# ATxmega384C3 device description
Architecture: AVR8_XMEGA; Family: AVR XMEGA
Registers are 8-bit, access not given, no defined reset value unless marked. A register's access mark holds for its fields unless they carry their own. Offsets are from the block's base; [hi:lo] are bit positions; {n}, {i} and the like mark numbered series; 'fields as' and 'values as' point back to an identical list.

## AWEX — Advanced Waveform Extension
Instances: AWEXC 0x880
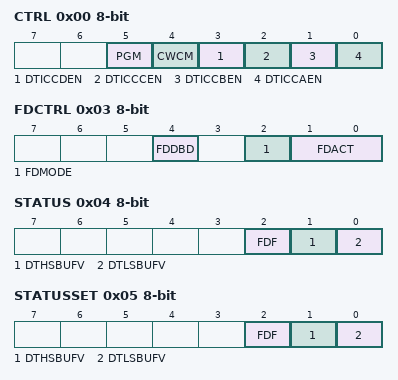
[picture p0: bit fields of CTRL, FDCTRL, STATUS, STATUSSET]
0x00 CTRL — Control Register
  [5] PGM — Pattern Generation Mode
  [4] CWCM — Common Waveform Channel Mode
  [3] DTICCDEN — Dead Time Insertion Compare Channel D Enable
  [2] DTICCCEN — Dead Time Insertion Compare Channel C Enable
  [1] DTICCBEN — Dead Time Insertion Compare Channel B Enable
  [0] DTICCAEN — Dead Time Insertion Compare Channel A Enable
0x02 FDEMASK — Fault Detection Event Mask
0x03 FDCTRL — Fault Detection Control Register
  [4] FDDBD — Fault Detect on Disable Break Disable
  [2] FDMODE — Fault Detect Mode
  [1:0] FDACT — Fault Detect Action
    0=NONE (No Fault Protection); 1=CLEAROE (Clear Output Enable Bits); 3=CLEARDIR (Clear I/O Port Direction Bits)
0x04 STATUS
  [2] FDF — Fault Detect Flag
  [1] DTHSBUFV — Dead Time High Side Buffer Valid
  [0] DTLSBUFV — Dead Time Low Side Buffer Valid
0x05 STATUSSET
  fields as STATUS
0x06 DTBOTH — Dead Time Both Sides
0x07 DTBOTHBUF — Dead Time Both Sides Buffer
0x08 DTLS — Dead Time Low Side
0x09 DTHS — Dead Time High Side
0x0A DTLSBUF — Dead Time Low Side Buffer
0x0B DTHSBUF — Dead Time High Side Buffer
0x0C OUTOVEN — Output Override Enable

## HIRES — High-Resolution Extension
Instances: HIRESC 0x890
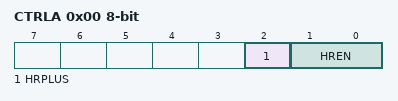
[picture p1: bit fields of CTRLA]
0x00 CTRLA — Control Register
  [2] HRPLUS — High Resolution Plus
  [1:0] HREN — High Resolution Enable
    0=NONE (No Fault Protection); 1=TC0 (Enable High Resolution on Timer/Counter 0); 2=TC1 (Enable High Resolution on Timer/Counter 1); 3=BOTH (Enable High Resolution both Timer/Counters)

## USART — Universal Synchronous/Asynchronous Receiver/Transmitter
Instances: USARTC0 0x8A0, USARTD0 0x9A0, USARTE0 0xAA0
0x00 DATA
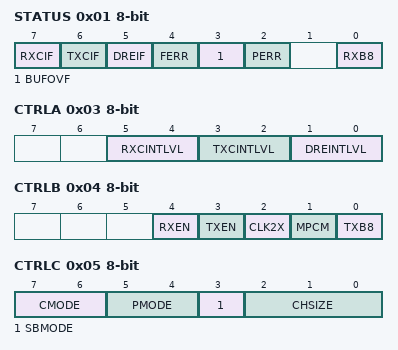
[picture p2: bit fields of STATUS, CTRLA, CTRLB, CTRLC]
0x01 STATUS
  [7] RXCIF — Receive Interrupt Flag
  [6] TXCIF — Transmit Interrupt Flag
  [5] DREIF — Data Register Empty Flag
  [4] FERR — Frame Error
  [3] BUFOVF — Buffer Overflow
  [2] PERR — Parity Error
  [0] RXB8 — Receive Bit 8
0x03 CTRLA — Control Register A
  [all] fields
    0=OFF (Interrupt Disabled); 1=LO (Low Level); 2=MED (Medium Level); 3=HI (High Level)
  [5:4] RXCINTLVL — Receive Interrupt Level
  [3:2] TXCINTLVL — Transmit Interrupt Level
  [1:0] DREINTLVL — Data Register Empty Interrupt Level
0x04 CTRLB — Control Register B
  [4] RXEN — Receiver Enable
  [3] TXEN — Transmitter Enable
  [2] CLK2X — Double transmission speed
  [1] MPCM — Multi-processor Communication Mode
  [0] TXB8 — Transmit bit 8
0x05 CTRLC — Control Register C
  [7:6] CMODE — Communication Mode
    0=ASYNCHRONOUS (Asynchronous Mode); 1=SYNCHRONOUS (Synchronous Mode); 2=IRDA (IrDA Mode); 3=MSPI (Master SPI Mode)
  [5:4] PMODE — Parity Mode
    0=DISABLED (No Parity); 2=EVEN (Even Parity); 3=ODD (Odd Parity)
  [3] SBMODE — Stop Bit Mode
  [2:0] CHSIZE — Character Size
    {v}={v+5}BIT (Character size: {v+5} bit) (v=0..3); 7=9BIT (Character size: 9 bit)
0x06 BAUDCTRLA — Baud Rate Control Register A
  [7:0] BSEL — Baud Rate Selection Bits [7:0]
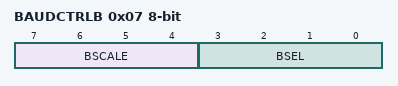
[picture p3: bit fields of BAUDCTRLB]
0x07 BAUDCTRLB — Baud Rate Control Register B
  [7:4] BSCALE — Baud Rate Scale
  [3:0] BSEL — Baud Rate Selection bits[11:8]

## SPI — Serial Peripheral Interface
Instances: SPIC 0x8C0, SPID 0x9C0
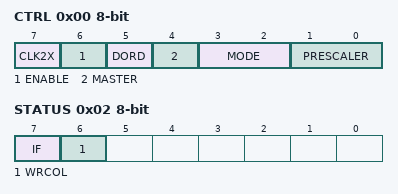
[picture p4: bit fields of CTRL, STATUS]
0x00 CTRL — Control Register
  [7] CLK2X — Enable Double Speed
  [6] ENABLE — Enable Module
  [5] DORD — Data Order Setting
  [4] MASTER — Master Operation Enable
  [3:2] MODE — SPI Mode
    {v}=SPI Mode {v} (v=0..3)
  [1:0] PRESCALER
    0=DIV4 (System Clock / 4); 1=DIV16 (System Clock / 16); 2=DIV64 (System Clock / 64); 3=DIV128 (System Clock / 128)
0x01 INTCTRL — Interrupt Control Register
  [1:0] INTLVL — Interrupt level
    0=OFF (Interrupt Disabled); 1=LO (Low Level); 2=MED (Medium Level); 3=HI (High Level)
0x02 STATUS
  [7] IF — Interrupt Flag
  [6] WRCOL — Write Collision
0x03 DATA

## IRCOM — IR Communication Module
Instances: IRCOM 0x8F8
0x00 CTRL — Control Register
  [3:0] EVSEL — Event Channel Select
    0=OFF (No Event Source); {v}=Event Channel {v-8} (v=8..11)
0x01 TXPLCTRL — IrDA Transmitter Pulse Length Control Register
0x02 RXPLCTRL — IrDA Receiver Pulse Length Control Register

## NVM_FUSES — Fuses
Instances: FUSE 0x00 in fuses
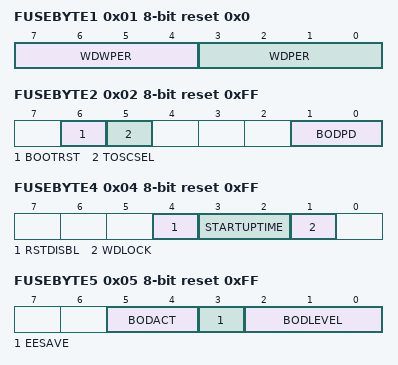
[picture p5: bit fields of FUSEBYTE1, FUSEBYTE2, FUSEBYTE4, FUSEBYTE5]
0x01 FUSEBYTE1 reset 0x0 — Watchdog Configuration
  [7:4] WDWPER — Watchdog Window Timeout Period
    0=8CLK (8 cycles (8ms @ 3.3V)); 1=16CLK (16 cycles (16ms @ 3.3V)); 2=32CLK (32 cycles (32ms @ 3.3V)); 3=64CLK (64 cycles (64ms @ 3.3V)); 4=128CLK (128 cycles (0.125s @ 3.3V)); 5=256CLK (256 cycles (0.25s @ 3.3V)); 6=512CLK (512 cycles (0.5s @ 3.3V)); 7=1KCLK (1K cycles (1s @ 3.3V)); 8=2KCLK (2K cycles (2s @ 3.3V)); 9=4KCLK (4K cycles (4s @ 3.3V)); 10=8KCLK (8K cycles (8s @ 3.3V))
  [3:0] WDPER — Watchdog Timeout Period
    values as WDWPER
0x02 FUSEBYTE2 reset 0xFF — Reset Configuration
  [6] BOOTRST — Boot Loader Section Reset Vector
    0=BOOTLDR (Boot Loader Reset); 1=APPLICATION (Application Reset)
  [5] TOSCSEL — Timer Oscillator pin location
    0=ALTERNATE (TOSC1 / TOSC2 on separate pins); 1=XTAL (TOSC1 / TOSC2 shared with XTAL1 / XTAL2)
  [1:0] BODPD — BOD Operation in Power-Down Mode
    1=SAMPLED (BOD enabled in sampled mode); 2=CONTINUOUS (BOD enabled continuously); 3=DISABLED (BOD Disabled)
0x04 FUSEBYTE4 reset 0xFF — Start-up Configuration
  [4] RSTDISBL — External Reset Disable
  [3:2] STARTUPTIME
    3=0MS; 1=4MS; 0=64MS
  [1] WDLOCK — Watchdog Timer Lock
0x05 FUSEBYTE5 reset 0xFF — EESAVE and BOD Level
  [5:4] BODACT — BOD Operation in Active Mode
    values as FUSEBYTE2.BODPD
  [3] EESAVE — Preserve EEPROM Through Chip Erase
  [2:0] BODLEVEL — Brownout Detection Voltage Level
    7=1V6 (1.6 V); 6=1V8 (1.8 V); 5=2V0 (2.0 V); 4=2V2 (2.2 V); 3=2V4 (2.4 V); 2=2V6 (2.6 V); 1=2V8 (2.8 V); 0=3V0 (3.0 V)

## NVM_LOCKBITS — Lock Bits
Instances: LOCKBIT 0x00 in lockbits
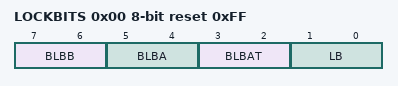
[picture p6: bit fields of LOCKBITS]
0x00 LOCKBITS reset 0xFF
  [7:6] BLBB — Boot Lock Bits - Boot Section
    0=RWLOCK (Read and write not allowed); 1=RLOCK (Read not allowed); 2=WLOCK (Write not allowed); 3=NOLOCK (No locks)
  [5:4] BLBA — Boot Lock Bits - Application Section
    values as BLBB
  [3:2] BLBAT — Boot Lock Bits - Application Table
    values as BLBB
  [1:0] LB — Lock Bits
    0=RWLOCK (Read and write not allowed); 2=WLOCK (Write not allowed); 3=NOLOCK (No locks)

## NVM_PROD_SIGNATURES (SIGROW module) — Production Signatures
Instances: PROD_SIGNATURES 0x00 in prod_signatures
0x00 RCOSC2M — RCOSC 2 MHz Calibration Value B
0x01 RCOSC2MA — RCOSC 2 MHz Calibration Value A
0x02 RCOSC32K — RCOSC 32.768 kHz Calibration Value
0x03 RCOSC32M — RCOSC 32 MHz Calibration Value B
0x04 RCOSC32MA — RCOSC 32 MHz Calibration Value A
{0x8+i} LOTNUM{i} (i=0..5) — Lot Number Byte {i}, ASCII
0x10 WAFNUM — Wafer Number
0x12 COORDX0 — Wafer Coordinate X Byte 0
0x13 COORDX1 — Wafer Coordinate X Byte 1
0x14 COORDY0 — Wafer Coordinate Y Byte 0
0x15 COORDY1 — Wafer Coordinate Y Byte 1
0x1A USBCAL0 — USB Calibration Byte 0
0x1B USBCAL1 — USB Calibration Byte 1
0x1C USBRCOSC — USB RCOSC Calibration Value B
0x1D USBRCOSCA — USB RCOSC Calibration Value A
0x20 ADCACAL0 — ADCA Calibration Byte 0
0x21 ADCACAL1 — ADCA Calibration Byte 1
0x2E TEMPSENSE0 — Temperature Sensor Calibration Byte 0
0x2F TEMPSENSE1 — Temperature Sensor Calibration Byte 1
